# R7FA2L1AB register map
Vendor: Renesas Electronics Corporation; Series: RA2L1; File version: 0.50.00
CPU: CM23 r1p0, little endian, MPU, no FPU, VTOR, 2 interrupt priority bits, 32 interrupts
Registers are 8-bit, read-write, reset 0x0 unless marked. A register's access mark holds for its fields unless they carry their own. Offsets are from the block's base; [hi:lo] are bit positions; {n}, {i} and the like mark numbered series; 'fields as' and 'values as' point back to an identical list; <NAME> marks a mode.

## GPT320 — General PWM 32-bit Timer 0
Base 0x40078000
Same registers: GPT321 0x40078100, GPT322 0x40078200, GPT323 0x40078300, GPT164 0x40078400, GPT165 0x40078500, GPT166 0x40078600, GPT167 0x40078700, GPT168 0x40078800, GPT169 0x40078900
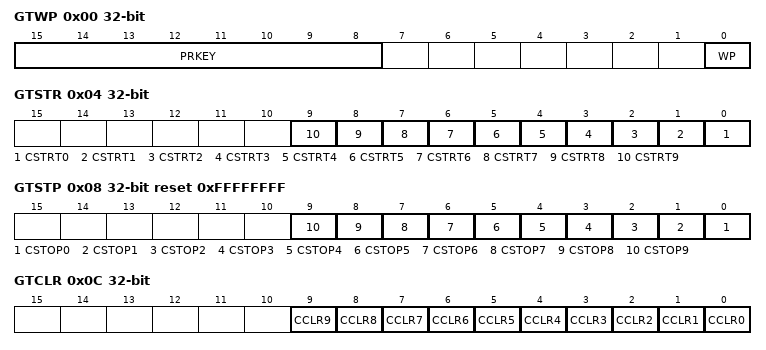
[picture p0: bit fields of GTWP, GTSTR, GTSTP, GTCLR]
0x00 GTWP 32-bit — General PWM Timer Write-Protection Register
  [15:8] PRKEY — GTWP Key Code
  [0] WP — Register Write Disable
    0=Write to the register enabled; 1=Write to the register disabled
0x04 GTSTR 32-bit — General PWM Timer Software Start Register
  [all] fields
    0=GTCNT counter not start; 1=GTCNT counter start
  [n] CSTRT{n} (n=0..9) — Channel n GTCNT Count Start (n : the same as bit position value)
0x08 GTSTP 32-bit reset 0xFFFFFFFF — General PWM Timer Software Stop Register
  [all] fields
    0=GTCNT counter not stop; 1=GTCNT counter stop
  [n] CSTOP{n} (n=0..9) — Channel n GTCNT Count Stop (n : the same as bit position value)
0x0C GTCLR 32-bit wo — General PWM Timer Software Clear Register
  [all] fields
    0=GTCNT counter is not cleared; 1=GTCNT counter is cleared
  [n] CCLR{n} (n=0..9) — Channel n GTCNT Count Clear (n : the same as bit position value)
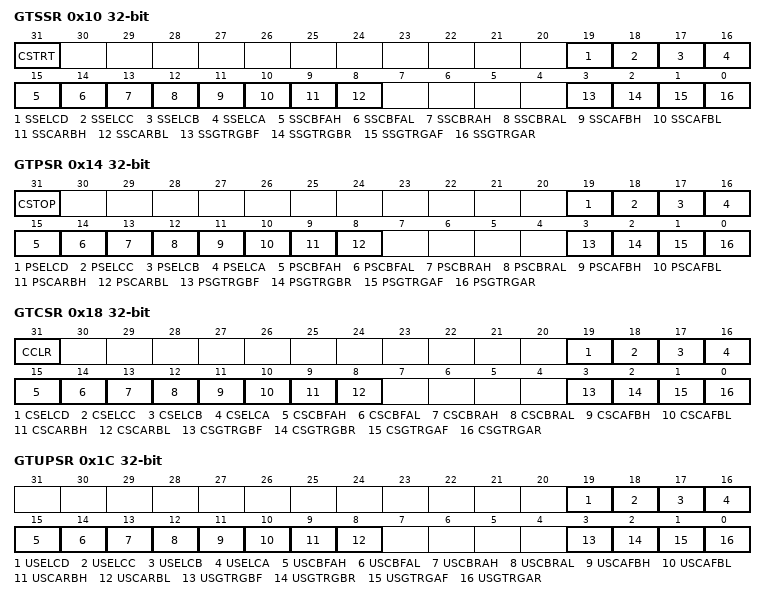
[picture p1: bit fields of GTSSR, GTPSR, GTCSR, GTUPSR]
0x10 GTSSR 32-bit — General PWM Timer Start Source Select Register
  [31] CSTRT — Software Source Counter Start Enable
    0=Counter start disabled by the GTSTR register; 1=Counter start enabled by the GTSTR register
  [19] SSELCD — ELC_GPTD Event Source Counter Start Enable
    0=Counter start disabled at the ELC_GPTD input; 1=Counter start enabled at the ELC_GPTD input
  [18] SSELCC — ELC_GPTC Event Source Counter Start Enable
    0=Counter start disabled at the ELC_GPTC input; 1=Counter start enabled at the ELC_GPTC input
  [17] SSELCB — ELC_GPTB Event Source Counter Start Enable
    0=Counter start disabled at the ELC_GPTB input; 1=Counter start enabled at the ELC_GPTB input
  [16] SSELCA — ELC_GPTA Event Source Counter Start Enable
    0=Counter start disabled at the ELC_GPTA input; 1=Counter start enabled at the ELC_GPTA input
  [15] SSCBFAH — GTIOCB Pin Falling Input during GTIOCA Value High Source Counter Start Enable
    0=Counter start disabled on the falling edge of GTIOCB input when GTIOCA input is 1; 1=Counter start enabled on the falling edge of GTIOCB input when GTIOCA input is 1
  [14] SSCBFAL — GTIOCB Pin Falling Input during GTIOCA Value Low Source Counter Start Enable
    0=Counter start disabled on the falling edge of GTIOCB input when GTIOCA input is 0; 1=Counter start enabled on the falling edge of GTIOCB input when GTIOCA input is 0
  [13] SSCBRAH — GTIOCB Pin Rising Input during GTIOCA Value High Source Counter Start Enable
    0=Counter start disabled on the rising edge of GTIOCB input when GTIOCA input is 1; 1=Counter start enabled on the rising edge of GTIOCB input when GTIOCA input is 1
  [12] SSCBRAL — GTIOCB Pin Rising Input during GTIOCA Value Low Source Counter Start Enable
    0=Counter start disabled on the rising edge of GTIOCB input when GTIOCA input is 0; 1=Counter start enabled on the rising edge of GTIOCB input when GTIOCA input is 0
  [11] SSCAFBH — GTIOCA Pin Falling Input during GTIOCB Value High Source Counter Start Enable
    0=Counter start disabled on the falling edge of GTIOCA input when GTIOCB input is 1; 1=Counter start enabled on the falling edge of GTIOCA input when GTIOCB input is 1
  [10] SSCAFBL — GTIOCA Pin Falling Input during GTIOCB Value Low Source Counter Start Enable
    0=Counter start disabled on the falling edge of GTIOCA input when GTIOCB input is 0; 1=Counter start enabled on the falling edge of GTIOCA input when GTIOCB input is 0
  [9] SSCARBH — GTIOCA Pin Rising Input during GTIOCB Value High Source Counter Start Enable
    0=Counter start disabled on the rising edge of GTIOCA input when GTIOCB input is 1; 1=Counter start enabled on the rising edge of GTIOCA input when GTIOCB input is 1
  [8] SSCARBL — GTIOCA Pin Rising Input during GTIOCB Value Low Source Counter Start Enable
    0=Counter start disabled on the rising edge of GTIOCA input when GTIOCB input is 0; 1=Counter start enabled on the rising edge of GTIOCA input when GTIOCB input is 0
  [3] SSGTRGBF — GTETRGB Pin Falling Input Source Counter Start Enable
    0=Counter start disabled on the falling edge of GTETRGB input; 1=Counter start enabled on the falling edge of GTETRGB input
  [2] SSGTRGBR — GTETRGB Pin Rising Input Source Counter Start Enable
    0=Counter start disabled on the rising edge of GTETRGB input; 1=Counter start enabled on the rising edge of GTETRGB input
  [1] SSGTRGAF — GTETRGA Pin Falling Input Source Counter Start Enable
    0=Counter start disabled on the falling edge of GTETRGA input; 1=Counter start enabled on the falling edge of GTETRGA input
  [0] SSGTRGAR — GTETRGA Pin Rising Input Source Counter Start Enable
    0=Counter start disabled on the rising edge of GTETRGA input; 1=Counter start enabled on the rising edge of GTETRGA input
0x14 GTPSR 32-bit — General PWM Timer Stop Source Select Register
  [31] CSTOP — Software Source Counter Stop Enable
    0=Counter stop disabled by the GTSTP register; 1=Counter stop enabled by the GTSTP register
  [19] PSELCD — ELC_GPTD Event Source Counter Stop Enable
    0=Counter stop disabled at the ELC_GPTD input; 1=Counter stop enabled at the ELC_GPTD input
  [18] PSELCC — ELC_GPTC Event Source Counter Stop Enable
    0=Counter stop disabled at the ELC_GPTC input; 1=Counter stop enabled at the ELC_GPTC input
  [17] PSELCB — ELC_GPTB Event Source Counter Stop Enable
    0=Counter stop disabled at the ELC_GPTB input; 1=Counter stop enabled at the ELC_GPTB input
  [16] PSELCA — ELC_GPTA Event Source Counter Stop Enable
    0=Counter stop disabled at the ELC_GPTA input; 1=Counter stop enabled at the ELC_GPTA input
  [15] PSCBFAH — GTIOCB Pin Falling Input during GTIOCA Value High Source Counter Stop Enable
    0=Counter stop disabled on the falling edge of GTIOCB input when GTIOCA input is 1; 1=Counter stop enabled on the falling edge of GTIOCB input when GTIOCA input is 1
  [14] PSCBFAL — GTIOCB Pin Falling Input during GTIOCA Value Low Source Counter Stop Enable
    0=Counter stop disabled on the falling edge of GTIOCB input when GTIOCA input is 0; 1=Counter stop enabled on the falling edge of GTIOCB input when GTIOCA input is 0
  [13] PSCBRAH — GTIOCB Pin Rising Input during GTIOCA Value High Source Counter Stop Enable
    0=Counter stop disabled on the rising edge of GTIOCB input when GTIOCA input is 1; 1=Counter stop enabled on the rising edge of GTIOCB input when GTIOCA input is 1
  [12] PSCBRAL — GTIOCB Pin Rising Input during GTIOCA Value Low Source Counter Stop Enable
    0=Counter stop disabled on the rising edge of GTIOCB input when GTIOCA input is 0; 1=Counter stop enabled on the rising edge of GTIOCB input when GTIOCA input is 0
  [11] PSCAFBH — GTIOCA Pin Falling Input during GTIOCB Value High Source Counter Stop Enable
    0=Counter stop disabled on the falling edge of GTIOCA input when GTIOCB input is 1; 1=Counter stop enabled on the falling edge of GTIOCA input when GTIOCB input is 1
  [10] PSCAFBL — GTIOCA Pin Falling Input during GTIOCB Value Low Source Counter Stop Enable
    0=Counter stop disabled on the falling edge of GTIOCA input when GTIOCB input is 0; 1=Counter stop enabled on the falling edge of GTIOCA input when GTIOCB input is 0
  [9] PSCARBH — GTIOCA Pin Rising Input during GTIOCB Value High Source Counter Stop Enable
    0=Counter stop disabled on the rising edge of GTIOCA input when GTIOCB input is 1; 1=Counter stop enabled on the rising edge of GTIOCA input when GTIOCB input is 1
  [8] PSCARBL — GTIOCA Pin Rising Input during GTIOCB Value Low Source Counter Stop Enable
    0=Counter stop disabled on the rising edge of GTIOCA input when GTIOCB input is 0; 1=Counter stop enabled on the rising edge of GTIOCA input when GTIOCB input is 0
  [3] PSGTRGBF — GTETRGB Pin Falling Input Source Counter Stop Enable
    0=Counter stop disabled on the falling edge of GTETRGB input; 1=Counter stop enabled on the falling edge of GTETRGB input
  [2] PSGTRGBR — GTETRGB Pin Rising Input Source Counter Stop Enable
    0=Counter stop disabled on the rising edge of GTETRGB input; 1=Counter stop enabled on the rising edge of GTETRGB input
  [1] PSGTRGAF — GTETRGA Pin Falling Input Source Counter Stop Enable
    0=Counter stop disabled on the falling edge of GTETRGA input; 1=Counter stop enabled on the falling edge of GTETRGA input
  [0] PSGTRGAR — GTETRGA Pin Rising Input Source Counter Stop Enable
    0=Counter stop disabled on the rising edge of GTETRGA input; 1=Counter stop enabled on the rising edge of GTETRGA input
0x18 GTCSR 32-bit — General PWM Timer Clear Source Select Register
  [31] CCLR — Software Source Counter Clear Enable
    0=Counter clear disabled by the GTCLR register; 1=Counter clear enabled by the GTCLR register
  [19] CSELCD — ELC_GPTD Event Source Counter Clear Enable
    0=Counter clear disabled at the ELC_GPTD input; 1=Counter clear enabled at the ELC_GPTD input
  [18] CSELCC — ELC_GPTC Event Source Counter Clear Enable
    0=Counter clear disabled at the ELC_GPTC input; 1=Counter clear enabled at the ELC_GPTC input
  [17] CSELCB — ELC_GPTB Event Source Counter Clear Enable
    0=Counter clear disabled at the ELC_GPTB input; 1=Counter clear enabled at the ELC_GPTB input
  [16] CSELCA — ELC_GPTA Event Source Counter Clear Enable
    0=Counter clear disabled at the ELC_GPTA input; 1=Counter clear enabled at the ELC_GPTA input
  [15] CSCBFAH — GTIOCB Pin Falling Input during GTIOCA Value High Source Counter Clear Enable
    0=Counter clear disabled on the falling edge of GTIOCB input when GTIOCA input is 1; 1=Counter clear enabled on the falling edge of GTIOCB input when GTIOCA input is 1
  [14] CSCBFAL — GTIOCB Pin Falling Input during GTIOCA Value Low Source Counter Clear Enable
    0=Counter clear disabled on the falling edge of GTIOCB input when GTIOCA input is 0; 1=Counter clear enabled on the falling edge of GTIOCB input when GTIOCA input is 0
  [13] CSCBRAH — GTIOCB Pin Rising Input during GTIOCA Value High Source Counter Clear Enable
    0=Counter clear disabled on the rising edge of GTIOCB input when GTIOCA input is 1; 1=Counter clear enabled on the rising edge of GTIOCB input when GTIOCA input is 1
  [12] CSCBRAL — GTIOCB Pin Rising Input during GTIOCA Value Low Source Counter Clear Enable
    0=Counter clear disabled on the rising edge of GTIOCB input when GTIOCA input is 0; 1=Counter clear enabled on the rising edge of GTIOCB input when GTIOCA input is 0
  [11] CSCAFBH — GTIOCA Pin Falling Input during GTIOCB Value High Source Counter Clear Enable
    0=Counter clear disabled on the falling edge of GTIOCA input when GTIOCB input is 1; 1=Counter clear enabled on the falling edge of GTIOCA input when GTIOCB input is 1
  [10] CSCAFBL — GTIOCA Pin Falling Input during GTIOCB Value Low Source Counter Clear Enable
    0=Counter clear disabled on the falling edge of GTIOCA input when GTIOCB input is 0; 1=Counter clear enabled on the falling edge of GTIOCA input when GTIOCB input is 0
  [9] CSCARBH — GTIOCA Pin Rising Input during GTIOCB Value High Source Counter Clear Enable
    0=Counter clear disabled on the rising edge of GTIOCA input when GTIOCB input is 1; 1=Counter clear enabled on the rising edge of GTIOCA input when GTIOCB input is 1
  [8] CSCARBL — GTIOCA Pin Rising Input during GTIOCB Value Low Source Counter Clear Enable
    0=Counter clear disabled on the rising edge of GTIOCA input when GTIOCB input is 0; 1=Counter clear enabled on the rising edge of GTIOCA input when GTIOCB input is 0
  [3] CSGTRGBF — GTETRGB Pin Falling Input Source Counter Clear Enable
    0=Counter clear disabled on the falling edge of GTETRGB input; 1=Counter clear enabled on the falling edge of GTETRGB input
  [2] CSGTRGBR — GTETRGB Pin Rising Input Source Counter Clear Enable
    0=Disable counter clear on the rising edge of GTETRGB input; 1=Enable counter clear on the rising edge of GTETRGB input
  [1] CSGTRGAF — GTETRGA Pin Falling Input Source Counter Clear Enable
    0=Counter clear disabled on the falling edge of GTETRGA input; 1=Counter clear enabled on the falling edge of GTETRGA input
  [0] CSGTRGAR — GTETRGA Pin Rising Input Source Counter Clear Enable
    0=Counter clear disabled on the rising edge of GTETRGA input; 1=Counter clear enabled on the rising edge of GTETRGA input
0x1C GTUPSR 32-bit — General PWM Timer Up Count Source Select Register
  [19] USELCD — ELC_GPTD Event Source Counter Count Up Enable
    0=Counter count up disabled at the ELC_GPTD input; 1=Counter count up enabled at the ELC_GPTD input
  [18] USELCC — ELC_GPTC Event Source Counter Count Up Enable
    0=Counter count up disabled at the ELC_GPTC input; 1=Counter count up enabled at the ELC_GPTC input
  [17] USELCB — ELC_GPTB Event Source Counter Count Up Enable
    0=Counter count up disabled at the ELC_GPTB input; 1=Counter count up enabled at the ELC_GPTB input
  [16] USELCA — ELC_GPTA Event Source Counter Count Up Enable
    0=Counter count up disabled at the ELC_GPTA input; 1=Counter count up enabled at the ELC_GPTA input
  [15] USCBFAH — GTIOCB Pin Falling Input during GTIOCA Value High Source Counter Count Up Enable
    0=Counter count up disabled on the falling edge of GTIOCB input when GTIOCA input is 1; 1=Counter count up enabled on the falling edge of GTIOCB input when GTIOCA input is 1
  [14] USCBFAL — GTIOCB Pin Falling Input during GTIOCA Value Low Source Counter Count Up Enable
    0=Counter count up disabled on the falling edge of GTIOCB input when GTIOCA input is 0; 1=Counter count up enabled on the falling edge of GTIOCB input when GTIOCA input is 0
  [13] USCBRAH — GTIOCB Pin Rising Input during GTIOCA Value High Source Counter Count Up Enable
    0=Counter count up disabled on the rising edge of GTIOCB input when GTIOCA input is 1; 1=Counter count up enabled on the rising edge of GTIOCB input when GTIOCA input is 1
  [12] USCBRAL — GTIOCB Pin Rising Input during GTIOCA Value Low Source Counter Count Up Enable
    0=Counter count up disabled on the rising edge of GTIOCB input when GTIOCA input is 0; 1=Counter count up enabled on the rising edge of GTIOCB input when GTIOCA input is 0
  [11] USCAFBH — GTIOCA Pin Falling Input during GTIOCB Value High Source Counter Count Up Enable
    0=Counter count up disabled on the falling edge of GTIOCA input when GTIOCB input is 1; 1=Counter count up enabled on the falling edge of GTIOCA input when GTIOCB input is 1
  [10] USCAFBL — GTIOCA Pin Falling Input during GTIOCB Value Low Source Counter Count Up Enable
    0=Counter count up disabled on the falling edge of GTIOCA input when GTIOCB input is 0; 1=Counter count up enabled on the falling edge of GTIOCA input when GTIOCB input is 0
  [9] USCARBH — GTIOCA Pin Rising Input during GTIOCB Value High Source Counter Count Up Enable
    0=Counter count up disabled on the rising edge of GTIOCA input when GTIOCB input is 1; 1=Counter count up enabled on the rising edge of GTIOCA input when GTIOCB input is 1
  [8] USCARBL — GTIOCA Pin Rising Input during GTIOCB Value Low Source Counter Count Up Enable
    0=Counter count up disabled on the rising edge of GTIOCA input when GTIOCB input is 0; 1=Counter count up enabled on the rising edge of GTIOCA input when GTIOCB input is 0
  [3] USGTRGBF — GTETRGB Pin Falling Input Source Counter Count Up Enable
    0=Counter count up disabled on the falling edge of GTETRGB input; 1=Counter count up enabled on the falling edge of GTETRGB input
  [2] USGTRGBR — GTETRGB Pin Rising Input Source Counter Count Up Enable
    0=Counter count up disabled on the rising edge of GTETRGB input; 1=Counter count up enabled on the rising edge of GTETRGB input
  [1] USGTRGAF — GTETRGA Pin Falling Input Source Counter Count Up Enable
    0=Counter count up disabled on the falling edge of GTETRGA input; 1=Counter count up enabled on the falling edge of GTETRGA input
  [0] USGTRGAR — GTETRGA Pin Rising Input Source Counter Count Up Enable
    0=Counter count up disabled on the rising edge of GTETRGA input; 1=Counter count up enabled on the rising edge of GTETRGA input
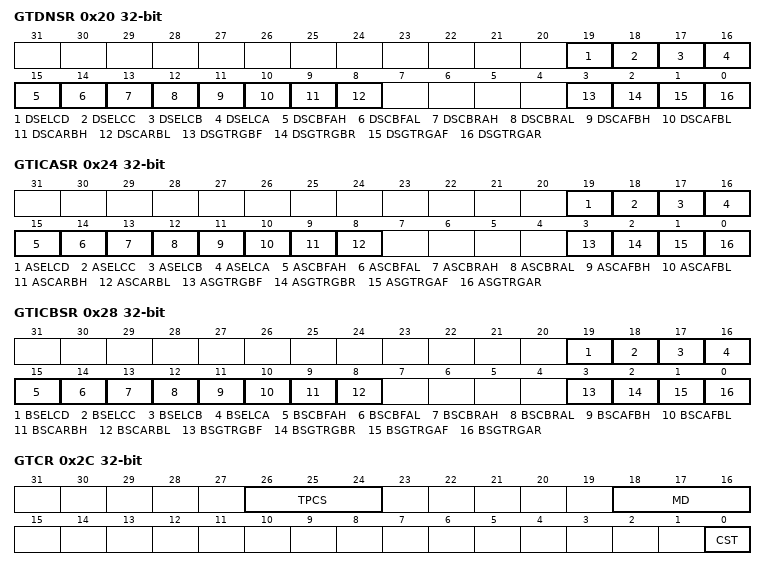
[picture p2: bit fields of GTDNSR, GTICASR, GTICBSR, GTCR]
0x20 GTDNSR 32-bit — General PWM Timer Down Count Source Select Register
  [19] DSELCD — ELC_GPTD Event Source Counter Count Down Enable
    0=Counter count down disabled at the ELC_GPTD input; 1=Counter count down enabled at the ELC_GPTD input
  [18] DSELCC — ELC_GPTC Event Source Counter Count Down Enable
    0=Counter count down disabled at the ELC_GPTC input; 1=Counter count down enabled at the ELC_GPTC input
  [17] DSELCB — ELC_GPTB Event Source Counter Count Down Enable
    0=Counter count down disabled at the ELC_GPTB input; 1=Counter count down enabled at the ELC_GPTB input
  [16] DSELCA — ELC_GPTA Event Source Counter Count Down Enable
    0=Counter count down disabled at the ELC_GPTA input; 1=Counter count down enabled at the ELC_GPTA input
  [15] DSCBFAH — GTIOCB Pin Falling Input during GTIOCA Value High Source Counter Count Down Enable
    0=Counter count down disabled on the falling edge of GTIOCB input when GTIOCA input is 1; 1=Counter count down enabled on the falling edge of GTIOCB input when GTIOCA input is 1
  [14] DSCBFAL — GTIOCB Pin Falling Input during GTIOCA Value Low Source Counter Count Down Enable
    0=Counter count down disabled on the falling edge of GTIOCB input when GTIOCA input is 0; 1=Counter count down enabled on the falling edge of GTIOCB input when GTIOCA input is 0
  [13] DSCBRAH — GTIOCB Pin Rising Input during GTIOCA Value High Source Counter Count Down Enable
    0=Counter count down disabled on the rising edge of GTIOCB input when GTIOCA input is 1; 1=Counter count down enabled on the rising edge of GTIOCB input when GTIOCA input is 1
  [12] DSCBRAL — GTIOCB Pin Rising Input during GTIOCA Value Low Source Counter Count Down Enable
    0=Counter count down disabled on the rising edge of GTIOCB input when GTIOCA input is 0; 1=Counter count down enabled on the rising edge of GTIOCB input when GTIOCA input is 0
  [11] DSCAFBH — GTIOCA Pin Falling Input during GTIOCB Value High Source Counter Count Down Enable
    0=Counter count down disabled on the falling edge of GTIOCA input when GTIOCB input is 1; 1=Counter count down enabled on the falling edge of GTIOCA input when GTIOCB input is 1
  [10] DSCAFBL — GTIOCA Pin Falling Input during GTIOCB Value Low Source Counter Count Down Enable
    0=Counter count down disabled on the falling edge of GTIOCA input when GTIOCB input is 0; 1=Counter count down enabled on the falling edge of GTIOCA input when GTIOCB input is 0
  [9] DSCARBH — GTIOCA Pin Rising Input during GTIOCB Value High Source Counter Count Down Enable
    0=Counter count down disabled on the rising edge of GTIOCA input when GTIOCB input is 1; 1=Counter count down enabled on the rising edge of GTIOCA input when GTIOCB input is 1
  [8] DSCARBL — GTIOCA Pin Rising Input during GTIOCB Value Low Source Counter Count Down Enable
    0=Counter count down disabled on the rising edge of GTIOCA input when GTIOCB input is 0; 1=Counter count down enabled on the rising edge of GTIOCA input when GTIOCB input is 0
  [3] DSGTRGBF — GTETRGB Pin Falling Input Source Counter Count Down Enable
    0=Counter count down disabled on the falling edge of GTETRGB input; 1=Counter count down enabled on the falling edge of GTETRGB input
  [2] DSGTRGBR — GTETRGB Pin Rising Input Source Counter Count Down Enable
    0=Counter count down disabled on the rising edge of GTETRGB input; 1=Counter count down enabled on the rising edge of GTETRGB input
  [1] DSGTRGAF — GTETRGA Pin Falling Input Source Counter Count Down Enable
    0=Counter count down disabled on the falling edge of GTETRGA input; 1=Counter count down enabled on the falling edge of GTETRGA input
  [0] DSGTRGAR — GTETRGA Pin Rising Input Source Counter Count Down Enable
    0=Counter count down disabled on the rising edge of GTETRGA input; 1=Counter count down enabled on the rising edge of GTETRGA input
0x24 GTICASR 32-bit — General PWM Timer Input Capture Source Select Register A
  [19] ASELCD — ELC_GPTD Event Source GTCCRA Input Capture Enable
    0=GTCCRA input capture disabled at the ELC_GPTD input; 1=GTCCRA input capture enabled at the ELC_GPTD input
  [18] ASELCC — ELC_GPTC Event Source GTCCRA Input Capture Enable
    0=GTCCRA input capture disabled at the ELC_GPTC input; 1=GTCCRA input capture enabled at the ELC_GPTC input
  [17] ASELCB — ELC_GPTB Event Source GTCCRA Input Capture Enable
    0=GTCCRA input capture disabled at the ELC_GPTB input; 1=GTCCRA input capture enabled at the ELC_GPTB input
  [16] ASELCA — ELC_GPTA Event Source GTCCRA Input Capture Enable
    0=GTCCRA input capture disabled at the ELC_GPTA input; 1=GTCCRA input capture enabled at the ELC_GPTA input
  [15] ASCBFAH — GTIOCB Pin Falling Input during GTIOCA Value High Source GTCCRA Input Capture Enable
    0=GTCCRA input capture disabled on the falling edge of GTIOCB input when GTIOCA input is 1; 1=GTCCRA input capture enabled on the falling edge of GTIOCB input when GTIOCA input is 1
  [14] ASCBFAL — GTIOCB Pin Falling Input during GTIOCA Value Low Source GTCCRA Input Capture Enable
    0=GTCCRA input capture disabled on the falling edge of GTIOCB input when GTIOCA input is 0; 1=GTCCRA input capture enabled on the falling edge of GTIOCB input when GTIOCA input is 0
  [13] ASCBRAH — GTIOCB Pin Rising Input during GTIOCA Value High Source GTCCRA Input Capture Enable
    0=GTCCRA input capture disabled on the rising edge of GTIOCB input when GTIOCA input is 1; 1=GTCCRA input capture enabled on the rising edge of GTIOCB input when GTIOCA input is 1
  [12] ASCBRAL — GTIOCB Pin Rising Input during GTIOCA Value Low Source GTCCRA Input Capture Enable
    0=GTCCRA input capture disabled on the rising edge of GTIOCB input when GTIOCA input is 0; 1=GTCCRA input capture enabled on the rising edge of GTIOCB input when GTIOCA input is 0
  [11] ASCAFBH — GTIOCA Pin Falling Input during GTIOCB Value High Source GTCCRA Input Capture Enable
    0=GTCCRA input capture disabled on the falling edge of GTIOCA input when GTIOCB input is 1; 1=GTCCRA input capture enabled on the falling edge of GTIOCA input when GTIOCB input is 1
  [10] ASCAFBL — GTIOCA Pin Falling Input during GTIOCB Value Low Source GTCCRA Input Capture Enable
    0=GTCCRA input capture disabled on the falling edge of GTIOCA input when GTIOCB input is 0; 1=GTCCRA input capture enabled on the falling edge of GTIOCA input when GTIOCB input is 0
  [9] ASCARBH — GTIOCA Pin Rising Input during GTIOCB Value High Source GTCCRA Input Capture Enable
    0=GTCCRA input capture disabled on the rising edge of GTIOCA input when GTIOCB input is 1; 1=GTCCRA input capture enabled on the rising edge of GTIOCA input when GTIOCB input is 1
  [8] ASCARBL — GTIOCA Pin Rising Input during GTIOCB Value Low Source GTCCRA Input Capture Enable
    0=GTCCRA input capture disabled on the rising edge of GTIOCA input when GTIOCB input is 0; 1=GTCCRA input capture enabled on the rising edge of GTIOCA input when GTIOCB input is 0
  [3] ASGTRGBF — GTETRGB Pin Falling Input Source GTCCRA Input Capture Enable
    0=GTCCRA input capture disabled on the falling edge of GTETRGB input; 1=GTCCRA input capture enabled on the falling edge of GTETRGB input
  [2] ASGTRGBR — GTETRGB Pin Rising Input Source GTCCRA Input Capture Enable
    0=GTCCRA input capture disabled on the rising edge of GTETRGB input; 1=GTCCRA input capture enabled on the rising edge of GTETRGB input
  [1] ASGTRGAF — GTETRGA Pin Falling Input Source GTCCRA Input Capture Enable
    0=GTCCRA input capture disabled on the falling edge of GTETRGA input; 1=GTCCRA input capture enabled on the falling edge of GTETRGA input
  [0] ASGTRGAR — GTETRGA Pin Rising Input Source GTCCRA Input Capture Enable
    0=GTCCRA input capture disabled on the rising edge of GTETRGA input; 1=GTCCRA input capture enabled on the rising edge of GTETRGA input
0x28 GTICBSR 32-bit — General PWM Timer Input Capture Source Select Register B
  [19] BSELCD — ELC_GPTD Event Source GTCCRB Input Capture Enable
    0=GTCCRB input capture disabled at the ELC_GPTD input; 1=GTCCRB input capture enabled at the ELC_GPTD input
  [18] BSELCC — ELC_GPTC Event Source GTCCRB Input Capture Enable
    0=GTCCRB input capture disabled at the ELC_GPTC input; 1=GTCCRB input capture enabled at the ELC_GPTC input
  [17] BSELCB — ELC_GPTB Event Source GTCCRB Input Capture Enable
    0=GTCCRB input capture disabled at the ELC_GPTB input; 1=GTCCRB input capture enabled at the ELC_GPTB input
  [16] BSELCA — ELC_GPTA Event Source GTCCRB Input Capture Enable
    0=GTCCRB input capture disabled at the ELC_GPTA input; 1=GTCCRB input capture enabled at the ELC_GPTA input
  [15] BSCBFAH — GTIOCB Pin Falling Input during GTIOCA Value High Source GTCCRB Input Capture Enable
    0=GTCCRB input capture disabled on the falling edge of GTIOCB input when GTIOCA input is 1; 1=GTCCRB input capture enabled on the falling edge of GTIOCB input when GTIOCA input is 1
  [14] BSCBFAL — GTIOCB Pin Falling Input during GTIOCA Value Low Source GTCCRB Input Capture Enable
    0=GTCCRB input capture disabled on the falling edge of GTIOCB input when GTIOCA input is 0; 1=GTCCRB input capture enabled on the falling edge of GTIOCB input when GTIOCA input is 0
  [13] BSCBRAH — GTIOCB Pin Rising Input during GTIOCA Value High Source GTCCRB Input Capture Enable
    0=GTCCRB input capture disabled on the rising edge of GTIOCB input when GTIOCA input is 1; 1=GTCCRB input capture enabled on the rising edge of GTIOCB input when GTIOCA input is 1
  [12] BSCBRAL — GTIOCB Pin Rising Input during GTIOCA Value Low Source GTCCRB Input Capture Enable
    0=GTCCRB input capture disabled on the rising edge of GTIOCB input when GTIOCA input is 0; 1=GTCCRB input capture enabled on the rising edge of GTIOCB input when GTIOCA input is 0
  [11] BSCAFBH — GTIOCA Pin Falling Input during GTIOCB Value High Source GTCCRB Input Capture Enable
    0=GTCCRB input capture disabled on the falling edge of GTIOCA input when GTIOCB input is 1; 1=GTCCRB input capture enabled on the falling edge of GTIOCA input when GTIOCB input is 1
  [10] BSCAFBL — GTIOCA Pin Falling Input during GTIOCB Value Low Source GTCCRB Input Capture Enable
    0=GTCCRB input capture disabled on the falling edge of GTIOCA input when GTIOCB input is 0; 1=GTCCRB input capture enabled on the falling edge of GTIOCA input when GTIOCB input is 0
  [9] BSCARBH — GTIOCA Pin Rising Input during GTIOCB Value High Source GTCCRB Input Capture Enable
    0=GTCCRB input capture disabled on the rising edge of GTIOCA input when GTIOCB input is 1; 1=GTCCRB input capture enabled on the rising edge of GTIOCA input when GTIOCB input is 1
  [8] BSCARBL — GTIOCA Pin Rising Input during GTIOCB Value Low Source GTCCRB Input Capture Enable
    0=GTCCRB input capture disabled on the rising edge of GTIOCA input when GTIOCB input is 0; 1=GTCCRB input capture enabled on the rising edge of GTIOCA input when GTIOCB input is 0
  [3] BSGTRGBF — GTETRGB Pin Falling Input Source GTCCRB Input Capture Enable
    0=GTCCRB input capture disabled on the falling edge of GTETRGB input; 1=GTCCRB input capture enabled on the falling edge of GTETRGB input
  [2] BSGTRGBR — GTETRGB Pin Rising Input Source GTCCRB Input Capture Enable
    0=GTCCRB input capture disabled on the rising edge of GTETRGB input; 1=GTCCRB input capture enabled on the rising edge of GTETRGB input
  [1] BSGTRGAF — GTETRGA Pin Falling Input Source GTCCRB Input Capture Enable
    0=GTCCRB input capture disabled on the falling edge of GTETRGA input; 1=GTCCRB input capture enabled on the falling edge of GTETRGA input
  [0] BSGTRGAR — GTETRGA Pin Rising Input Source GTCCRB Input Capture Enable
    0=GTCCRB input capture disabled on the rising edge of GTETRGA input; 1=GTCCRB input capture enabled on the rising edge of GTETRGA input
0x2C GTCR 32-bit — General PWM Timer Control Register
  [26:24] TPCS — Timer Prescaler Select
    0=PCLKD/1; 1=PCLKD/4; 2=PCLKD/16; 3=PCLKD/64; 4=PCLKD/256; 5=PCLKD/1024
  [18:16] MD — Mode Select
    0=Saw-wave PWM mode (single buffer or double buffer possible); 1=Saw-wave one-shot pulse mode (fixed buffer operation); 2=Setting prohibited; 3=Setting prohibited; 4=Triangle-wave PWM mode 1 (32-bit transfer at trough) (single buffer or double buffer is possible); 5=Triangle-wave PWM mode 2 (32-bit transfer at crest and trough) (single buffer or double buffer is possible); 6=Triangle-wave PWM mode 3 (64-bit transfer at trough) (fixed buffer operation); 7=Setting prohibited
  [0] CST — Count Start
    0=Count operation is stopped; 1=Count operation is performed
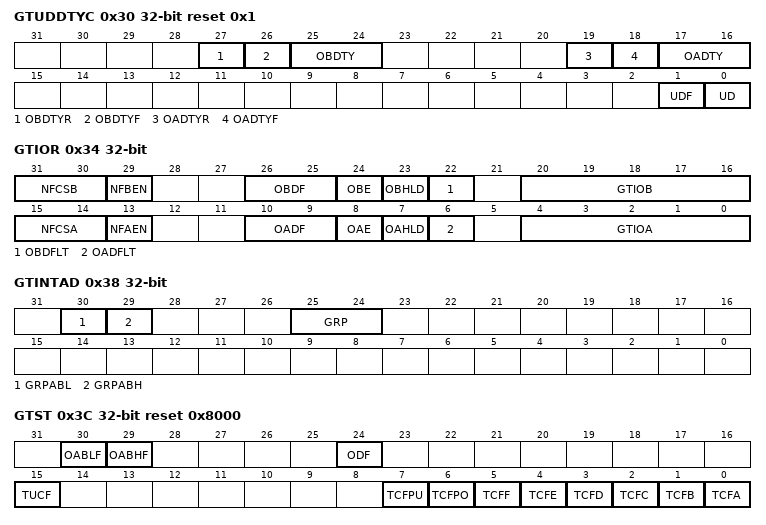
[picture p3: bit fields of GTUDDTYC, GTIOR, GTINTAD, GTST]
0x30 GTUDDTYC 32-bit reset 0x1 — General PWM Timer Count Direction and Duty Setting Register
  [27] OBDTYR — GTIOCB Output Value Selecting after Releasing 0%/100% Duty Setting
    0=Apply output value set in 0%/100% duty to GTIOB[3:2] function after releasing 0%/100% duty setting; 1=Apply masked compare match output value to GTIOB[3:2] function after releasing 0%/100% duty setting
  [26] OBDTYF — Forcible GTIOCB Output Duty Setting
    0=Not forcibly set; 1=Forcibly set
  [25:24] OBDTY — GTIOCB Output Duty Setting
    0=GTIOCB pin duty depends on the compare match; 1=GTIOCB pin duty depends on the compare match; 2=GTIOCB pin duty 0%; 3=GTIOCB pin duty 100%
  [19] OADTYR — GTIOCA Output Value Selecting after Releasing 0%/100% Duty Setting
    0=Apply output value set in 0%/100% duty to GTIOA[3:2] function after releasing 0%/100% duty setting; 1=Apply masked compare match output value to GTIOA[3:2] function after releasing 0%/100% duty setting
  [18] OADTYF — Forcible GTIOCA Output Duty Setting
    0=Not forcibly set; 1=Forcibly set
  [17:16] OADTY — GTIOCA Output Duty Setting
    0=GTIOCA pin duty depends on the compare match; 1=GTIOCA pin duty depends on the compare match; 2=GTIOCA pin duty 0%; 3=GTIOCA pin duty 100%
  [1] UDF — Forcible Count Direction Setting
    0=Not forcibly set; 1=Forcibly set
  [0] UD — Count Direction Setting
    0=GTCNT counts down; 1=GTCNT counts up
0x34 GTIOR 32-bit — General PWM Timer I/O Control Register
  [31:30] NFCSB — Noise Filter B Sampling Clock Select
    0=PCLKD/1; 1=PCLKD/4; 2=PCLKD/16; 3=PCLKD/64
  [29] NFBEN — Noise Filter B Enable
    0=The noise filter for the GTIOCB pin is disabled; 1=The noise filter for the GTIOCB pin is enabled
  [26:25] OBDF — GTIOCB Pin Disable Value Setting
    0=Output disable is prohibited; 1=GTIOCB pin is set to Hi-Z on output disable; 2=GTIOCB pin is set to 0 on output disable; 3=GTIOCB pin is set to 1 on output disable
  [24] OBE — GTIOCB Pin Output Enable
    0=Output is disabled; 1=Output is enabled
  [23] OBHLD — GTIOCB Pin Output Setting at the Start/Stop Count
    0=The GTIOCB pin output level at the start/stop of counting depends on the register setting; 1=The GTIOCB pin output level is retained at the start/stop of counting
  [22] OBDFLT — GTIOCB Pin Output Value Setting at the Count Stop
    0=The GTIOCB pin outputs low when counting stops; 1=The GTIOCB pin outputs high when counting stops
  [20:16] GTIOB — GTIOCB Pin Function Select
  [15:14] NFCSA — Noise Filter A Sampling Clock Select
    0=PCLKD/1; 1=PCLKD/4; 2=PCLKD/16; 3=PCLKD/64
  [13] NFAEN — Noise Filter A Enable
    0=The noise filter for the GTIOCA pin is disabled; 1=The noise filter for the GTIOCA pin is enabled
  [10:9] OADF — GTIOCA Pin Disable Value Setting
    0=Output disable is prohibited; 1=GTIOCA pin is set to Hi-Z on output disable; 2=GTIOCA pin is set to 0 on output disable; 3=GTIOCA pin is set to 1 on output disable
  [8] OAE — GTIOCA Pin Output Enable
    0=Output is disabled; 1=Output is enabled
  [7] OAHLD — GTIOCA Pin Output Setting at the Start/Stop Count
    0=The GTIOCA pin output level at the start or stop of counting depends on the register setting; 1=The GTIOCA pin output level is retained at the start or stop of counting
  [6] OADFLT — GTIOCA Pin Output Value Setting at the Count Stop
    0=The GTIOCA pin outputs low when counting stops; 1=The GTIOCA pin outputs high when counting stops
  [4:0] GTIOA — GTIOCA Pin Function Select
0x38 GTINTAD 32-bit — General PWM Timer Interrupt Output Setting Register
  [30] GRPABL — Same Time Output Level Low Disable Request Enable
    0=Same time output level low disable request disabled; 1=Same time output level low disable request enabled
  [29] GRPABH — Same Time Output Level High Disable Request Enable
    0=Same time output level high disable request disabled; 1=Same time output level high disable request enabled
  [25:24] GRP — Output Disable Source Select
    0=Group A output disable request; 1=Group B output disable request; other=Others (Setting prohibited)
0x3C GTST 32-bit reset 0x8000 — General PWM Timer Status Register
  [30] OABLF ro — Same Time Output Level Low Flag
    0=GTIOCA pin and GTIOCB pin do not output 0 at the same time; 1=GTIOCA pin and GTIOCB pin output 0 at the same time
  [29] OABHF ro — Same Time Output Level High Flag
    0=GTIOCA pin and GTIOCB pin do not output 1 at the same time; 1=GTIOCA pin and GTIOCB pin output 1 at the same time
  [24] ODF ro — Output Disable Flag
    0=No output disable request is generated; 1=An output disable request is generated
  [15] TUCF ro — Count Direction Flag
    0=GTCNT counter counts downward; 1=GTCNT counter counts upward
  [7] TCFPU — Underflow Flag
    0=No underflow (trough) occurred; 1=An underflow (trough) occurred
  [6] TCFPO — Overflow Flag
    0=No overflow (crest) occurred; 1=An overflow (crest) occurred
  [5] TCFF — Input Compare Match Flag F
    0=No compare match of GTCCRF is generated; 1=A compare match of GTCCRF is generated
  [4] TCFE — Input Compare Match Flag E
    0=No compare match of GTCCRE is generated; 1=A compare match of GTCCRE is generated
  [3] TCFD — Input Compare Match Flag D
    0=No compare match of GTCCRD is generated; 1=A compare match of GTCCRD is generated
  [2] TCFC — Input Compare Match Flag C
    0=No compare match of GTCCRC is generated; 1=A compare match of GTCCRC is generated
  [1] TCFB — Input Capture/Compare Match Flag B
    0=No input capture/compare match of GTCCRB is generated; 1=An input capture/compare match of GTCCRB is generated
  [0] TCFA — Input Capture/Compare Match Flag A
    0=No input capture/compare match of GTCCRA is generated; 1=An input capture/compare match of GTCCRA is generated
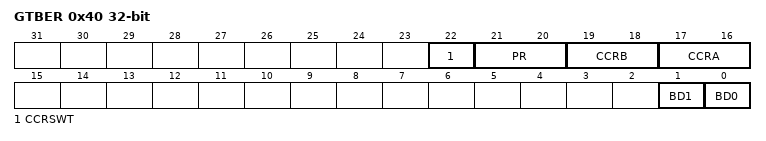
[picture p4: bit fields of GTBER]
0x40 GTBER 32-bit — General PWM Timer Buffer Enable Register
  [22] CCRSWT — GTCCRA and GTCCRB Forcible Buffer Operation
  [21:20] PR — GTPR Buffer Operation
    0=No buffer operation; 1=Single buffer operation (GTPBR --> GTPR); other=Others (Setting prohibited)
  [19:18] CCRB — GTCCRB Buffer Operation
    0=No buffer operation; 1=Single buffer operation (GTCCRB <----> GTCCRE); other=Others (Double buffer operation (GTCCRB <----> GTCCRE <----> GTCCRF))
  [17:16] CCRA — GTCCRA Buffer Operation
    0=No buffer operation; 1=Single buffer operation (GTCCRA <---->GTCCRC); other=Others (Double buffer operation (GTCCRA <----> GTCCRC <----> GTCCRD))
  [1] BD1 — GTPR Buffer Operation Disable
    0=Buffer operation is enabled; 1=Buffer operation is disabled
  [0] BD0 — GTCCR Buffer Operation Disable
    values as BD1
0x48 GTCNT 32-bit — General PWM Timer Counter
0x4C GTCCRA 32-bit reset 0xFFFFFFFF — General PWM Timer Compare Capture Register A
0x50 GTCCRB 32-bit reset 0xFFFFFFFF — General PWM Timer Compare Capture Register B
0x54 GTCCRC 32-bit reset 0xFFFFFFFF — General PWM Timer Compare Capture Register C
0x58 GTCCRE 32-bit reset 0xFFFFFFFF — General PWM Timer Compare Capture Register E
0x5C GTCCRD 32-bit reset 0xFFFFFFFF — General PWM Timer Compare Capture Register D
0x60 GTCCRF 32-bit reset 0xFFFFFFFF — General PWM Timer Compare Capture Register F
0x64 GTPR 32-bit reset 0xFFFFFFFF — General PWM Timer Cycle Setting Register
0x68 GTPBR 32-bit reset 0xFFFFFFFF — General PWM Timer Cycle Setting Buffer Register
0x88 GTDTCR 32-bit — General PWM Timer Dead Time Control Register
  [0] TDE — Negative-Phase Waveform Setting
    0=GTCCRB is set without using GTDVU; 1=GTDVU sets the compare match value for negative-phase waveform with automatic dead time in GTCCRB
0x8C GTDVU 32-bit reset 0xFFFFFFFF — General PWM Timer Dead Time Value Register U
